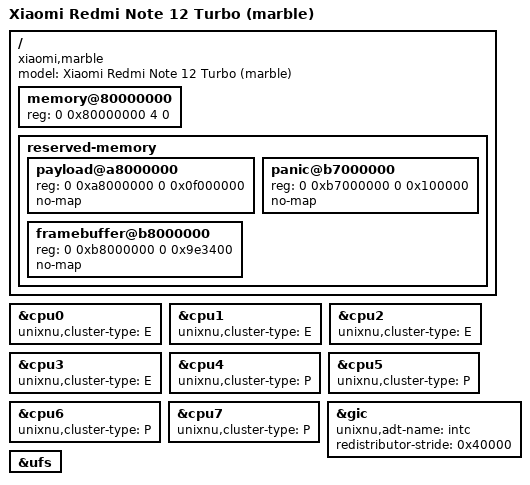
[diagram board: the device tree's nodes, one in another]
/dts-v1/;
/include/ "sm7475.dtsi"

/ {
    model = "Xiaomi Redmi Note 12 Turbo (marble)";
    compatible = "xiaomi,marble", "qcom,sm7475";
    memory@80000000 {
        device_type = "memory";
        // Existing board handoff range; runtime allocations come from UEFI.
        reg = <0 0x80000000 4 0>;
    };
    reserved-memory {
        #address-cells = <2>;
        #size-cells = <2>;
        ranges;
        payload@a8000000 { reg = <0 0xa8000000 0 0x0f000000>; no-map; };
        panic@b7000000 { reg = <0 0xb7000000 0 0x100000>; no-map; };
        framebuffer@b8000000 { reg = <0 0xb8000000 0 0x9e3400>; no-map; };
    };
};

&cpu0 { status = "okay"; unixnu,cluster-type = "E"; };
&cpu1 { status = "okay"; unixnu,cluster-type = "E"; };
&cpu2 { status = "okay"; unixnu,cluster-type = "E"; };
&cpu3 { status = "okay"; unixnu,cluster-type = "E"; };
&cpu4 { status = "okay"; unixnu,cluster-type = "P"; };
&cpu5 { status = "okay"; unixnu,cluster-type = "P"; };
&cpu6 { status = "okay"; unixnu,cluster-type = "P"; };
&cpu7 { status = "okay"; unixnu,cluster-type = "P"; };
&gic {
    unixnu,adt-name = "intc";
    // The running board firmware describes 256 KiB redistributor frames.
    redistributor-stride = /bits/ 64 <0x40000>;
};
// MarbleRootDisk publishes the UFS provider and owns its absolute MMIO windows.
&ufs { status = "okay"; };
// The iOS 27 target gives USB ownership to XNU and enables all eight cores.
